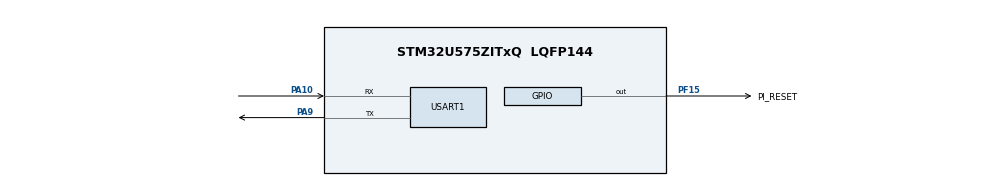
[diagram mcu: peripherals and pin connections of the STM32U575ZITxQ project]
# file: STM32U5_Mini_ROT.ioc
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CORTEX_M33_NS.userName=CORTEX_M33
Mcu.Family=STM32U5
Mcu.Name=STM32U575ZITxQ
Mcu.Package=LQFP144
NVIC.PriorityGroup=NVIC_PRIORITYGROUP_4
PA10.Mode=Asynchronous
PA10.Signal=USART1_RX
PA13\ (JTMS/SWDIO).Mode=Serial_Wire
PA13\ (JTMS/SWDIO).Signal=DEBUG_JTMS-SWDIO
PA14\ (JTCK/SWCLK).Mode=Serial_Wire
PA14\ (JTCK/SWCLK).Signal=DEBUG_JTCK-SWCLK
PA9.Mode=Asynchronous
PA9.Signal=USART1_TX
PF15.GPIO_Label=PI_RESET
PF15.GPIO_ModeDefaultOutputPP=GPIO_MODE_OUTPUT_OD
PF15.GPIO_PuPd=GPIO_NOPULL
PF15.Signal=GPIO_Output
PH0-OSC_IN\ (PH0).Mode=HSE-External-Oscillator
PH0-OSC_IN\ (PH0).Signal=RCC_OSC_IN
PH1-OSC_OUT\ (PH1).Mode=HSE-External-Oscillator
PH1-OSC_OUT\ (PH1).Signal=RCC_OSC_OUT
ProjectManager.HeapSize=0x200
ProjectManager.StackSize=0x400
ProjectManager.TargetToolchain=STM32CubeIDE
RCC.ADCFreq_Value=16000000
RCC.EPOD_VALUE=4000000
RCC.HSE_VALUE=16000000
RCC.HSI48_VALUE=48000000
RCC.HSI_VALUE=16000000
RCC.LSE_VALUE=32768
RCC.LSIDIV_VALUE=32000
RCC.MSI_VALUE=4000000
RCC.USBFreq_Value=48000000
RCC.VCOOutputFreq_Value=516000000
USART1.VirtualMode-Asynchronous=VM_ASYNC
VP_LPBAMQUEUE_VS_QUEUE.Mode=QUEUEMODE
VP_LPBAM_VS_SIG1.Mode=SmartRun
VP_LPBAM_VS_SIG4.Mode=LPDMA1
VP_MEMORYMAP_VS_MEMORYMAP.Mode=CurAppReg
VP_PWR_VS_SECSignals.Mode=Security/Privilege
VP_RNG_VS_RNG.Mode=RNG_Activate
board=custom

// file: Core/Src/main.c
/* USER CODE BEGIN Header */
/**
  ******************************************************************************
  * @file           : main.c
  * @brief          : Main program body
  ******************************************************************************
  * @attention
  *
  * Copyright (c) 2026 STMicroelectronics.
  * All rights reserved.
  *
  * This software is licensed under terms that can be found in the LICENSE file
  * in the root directory of this software component.
  * If no LICENSE file comes with this software, it is provided AS-IS.
  *
  ******************************************************************************
  */
/* USER CODE END Header */
#include "main.h"
#include "rng.h"
#include "usart.h"
#include "gpio.h"

/* USER CODE BEGIN Includes */
#include "uart_utils.h"
/**
 * @file uart_utils.c
 * @brief UART Communication Utilities
 * @description Printf redirection for debug output via UART
 */
#include "rot_core.h"
/**
 * @file rot_core.c
 * @brief Root of Trust Core Implementation
 * @description Hardware-level secure boot control and verification logic
 */
/* USER CODE END Includes */

void SystemClock_Config(void);

int main(void)
{

  /* MCU Configuration--------------------------------------------------------*/

  /* Reset of all peripherals, Initializes the Flash interface and the Systick. */
  HAL_Init();

  /* USER CODE BEGIN Init */
  MX_GPIO_Init();
  HAL_GPIO_WritePin(PI_RESET_GPIO_Port, PI_RESET_Pin, GPIO_PIN_RESET);
  /* USER CODE END Init */

  /* Configure the system clock */
  SystemClock_Config();

  /* Initialize all configured peripherals */
  MX_GPIO_Init();
  MX_USART1_UART_Init();
  MX_RNG_Init();
  /* USER CODE BEGIN 2 */
  ROT_System_Init();
  ROT_SecureBoot_Sequence();
  /* USER CODE END 2 */

  /* Infinite loop */
  while (1)
  {

  }
}

void SystemClock_Config(void)
{
  RCC_OscInitTypeDef RCC_OscInitStruct = {0};
  RCC_ClkInitTypeDef RCC_ClkInitStruct = {0};

  /** Configure the main internal regulator output voltage
  */
  if (HAL_PWREx_ControlVoltageScaling(PWR_REGULATOR_VOLTAGE_SCALE3) != HAL_OK)
  {
    Error_Handler();
  }

  /** Initializes the CPU, AHB and APB buses clocks
  */
  RCC_OscInitStruct.OscillatorType = RCC_OSCILLATORTYPE_HSI48|RCC_OSCILLATORTYPE_MSI;
  RCC_OscInitStruct.HSI48State = RCC_HSI48_ON;
  RCC_OscInitStruct.MSIState = RCC_MSI_ON;
  RCC_OscInitStruct.MSICalibrationValue = RCC_MSICALIBRATION_DEFAULT;
  RCC_OscInitStruct.MSIClockRange = RCC_MSIRANGE_4;
  RCC_OscInitStruct.PLL.PLLState = RCC_PLL_NONE;
  if (HAL_RCC_OscConfig(&RCC_OscInitStruct) != HAL_OK)
  {
    Error_Handler();
  }

  /** Initializes the CPU, AHB and APB buses clocks
  */
  RCC_ClkInitStruct.ClockType = RCC_CLOCKTYPE_HCLK|RCC_CLOCKTYPE_SYSCLK
                              |RCC_CLOCKTYPE_PCLK1|RCC_CLOCKTYPE_PCLK2
                              |RCC_CLOCKTYPE_PCLK3;
  RCC_ClkInitStruct.SYSCLKSource = RCC_SYSCLKSOURCE_MSI;
  RCC_ClkInitStruct.AHBCLKDivider = RCC_SYSCLK_DIV1;
  RCC_ClkInitStruct.APB1CLKDivider = RCC_HCLK_DIV1;
  RCC_ClkInitStruct.APB2CLKDivider = RCC_HCLK_DIV1;
  RCC_ClkInitStruct.APB3CLKDivider = RCC_HCLK_DIV1;

  if (HAL_RCC_ClockConfig(&RCC_ClkInitStruct, FLASH_LATENCY_0) != HAL_OK)
  {
    Error_Handler();
  }
}

void Error_Handler(void)
{
  __disable_irq();
  while (1)
  {
  }
}
